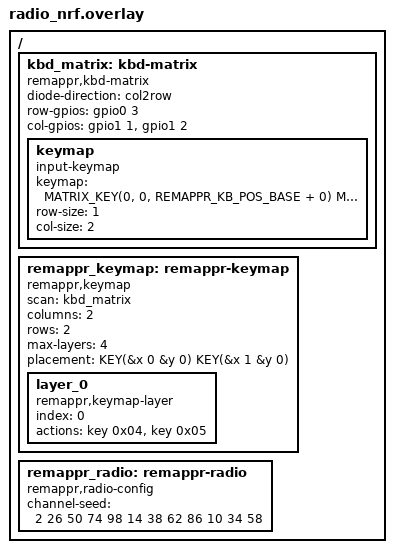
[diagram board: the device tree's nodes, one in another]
/*
 * Radio nRF — Remappr shield (generated by remappr).
 *
 * Drop this directory into a remappr-firmware checkout under
 * boards/shields/radio_nrf/ and build with -Dremappr_SHIELD=radio_nrf. Verify the
 * row/col GPIO specs against your wiring — remappr derives the matrix
 * cells from physical key position, not the electrical matrix.
 *
 * SPDX-License-Identifier: Apache-2.0
 */

#include <zephyr/dt-bindings/input/input-event-codes.h>
#include <zephyr/dt-bindings/input/keymap.h>
#include <dt-bindings/remappr/keys.h>
#include <dt-bindings/remappr/layout.h>
#include <remappr/keymap-tokens.dtsi>
#include <remappr/behavior-tokens.dtsi>

/ {
	kbd_matrix: kbd-matrix {
		compatible = "remappr,kbd-matrix";
		diode-direction = "col2row";
		row-gpios =
			<&gpio0 3 (GPIO_ACTIVE_HIGH | GPIO_PULL_DOWN)>;
		col-gpios =
			<&gpio1 1 GPIO_ACTIVE_HIGH>,
			<&gpio1 2 GPIO_ACTIVE_HIGH>;

		keymap {
			compatible = "input-keymap";
			keymap = <
				MATRIX_KEY(0, 0, REMAPPR_KB_POS_BASE + 0) MATRIX_KEY(0, 1, REMAPPR_KB_POS_BASE + 1)
			>;
			row-size = <1>;
			col-size = <2>;
		};
	};

	remappr_keymap: remappr-keymap {
		compatible = "remappr,keymap";
		scan = <&kbd_matrix>;
		columns = <2>;
		rows = <2>;
		max-layers = <4>;
		placement = <
				KEY(&x 0 &y 0) KEY(&x 1 &y 0)
		>;
		layer_0 {
			compatible = "remappr,keymap-layer";
			index = <0>;
			actions = <
				&key 0x04 &key 0x05
			>;
		};
	};
};

/ {
	remappr_radio: remappr-radio {
		compatible = "remappr,radio-config";
		channel-seed = /bits/ 8 <2 26 50 74 98 14 38 62 86 10 34 58>;
	};
};
